VERSION ""

NS_ :

BS_:

BU_: Tester FrontECU MyECU
VAL_TABLE_ SeatHeatLevel 3 "Level3" 2 "Level2" 1 "Level1" 0 "None" ;
VAL_TABLE_ SeatVentilationLevel 3 "Level3" 2 "Level2" 1 "Level1" 0 "None" ;
VAL_TABLE_ PowerModeStatus 3 "ACC" 2 "RUN" 1 "ACC" 0 "OFF" ;

BO_ 3221225472 VECTOR__INDEPENDENT_SIG_MSG: 0 Vector__XXX
 SG_ WindowStatus : 0|4@0+ (1,0) [0|15] "" Vector__XXX
 SG_ SteeringWheelAngle : 0|16@0- (0.1,0) [-3276.8|3276.7] "" Vector__XXX
 SG_ DoorStatus : 0|4@0+ (1,0) [0|15] "" Vector__XXX
 SG_ BrakePedalPosition : 0|10@0+ (0.1,0) [0|102.3] "" Vector__XXX
 SG_ AccPedalPosition : 0|10@0+ (0.1,0) [0|102.3] "" Vector__XXX
 SG_ HeadLampStatus : 0|4@0+ (1,0) [0|15] "" Vector__XXX

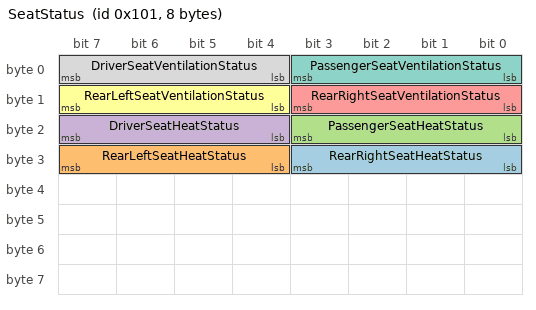
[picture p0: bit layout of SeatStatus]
BO_ 257 SeatStatus: 8 MyECU
 SG_ RearRightSeatHeatStatus : 27|4@0+ (1,0) [0|15] ""  FrontECU
 SG_ RearLeftSeatHeatStatus : 31|4@0+ (1,0) [0|15] ""  FrontECU
 SG_ PassengerSeatHeatStatus : 19|4@0+ (1,0) [0|15] ""  FrontECU
 SG_ DriverSeatHeatStatus : 23|4@0+ (1,0) [0|15] ""  FrontECU
 SG_ RearRightSeatVentilationStatus : 11|4@0+ (1,0) [0|15] ""  FrontECU
 SG_ RearLeftSeatVentilationStatus : 15|4@0+ (1,0) [0|15] ""  FrontECU
 SG_ PassengerSeatVentilationStatus : 3|4@0+ (1,0) [0|15] ""  FrontECU
 SG_ DriverSeatVentilationStatus : 7|4@0+ (1,0) [0|15] ""  FrontECU

CM_ BO_ 3221225472 "This is a message for not used signals, created by Vector CANdb++ DBC OLE DB Provider.";
BA_DEF_ BO_  "GenMsgCycleTime" INT 0 0;
BA_DEF_ BO_  "GenMsgSendType" ENUM  "Cyclic","spontanX","cyclicIfActiveX","spontanWithDelay","cyclicAndSpontanX","cyclicAndSpontanWithDelay","spontanWithRepetition","cyclicIfActiveAndSpontanWD","cyclicIfActiveFast","cyclicWithRepeatOnDemand";
BA_DEF_ SG_  "GenSigSendType" ENUM  "Cyclic","spontanX","cyclicIfActiveX","spontanWithDelay","cyclicAndSpontanX","cyclicAndSpontanWithDelay","spontanWithRepetition","cyclicIfActiveAndSpontanWD","cyclicIfActiveFast","cyclicWithRepeatOnDemand","none","NotUsed","NotUsed";
BA_DEF_  "Baudrate" INT 0 1000000;
BA_DEF_  "BusType" STRING ;
BA_DEF_  "NmType" STRING ;
BA_DEF_  "Manufacturer" STRING ;
BA_DEF_  "NmAsrWaitBusSleepTime" INT 0 65535;
BA_DEF_  "NmAsrTimeoutTime" INT 0 65535;
BA_DEF_  "NmAsrRepeatMessageTime" INT 0 65535;
BA_DEF_ BU_  "NmAsrNodeIdentifier" INT 0 255;
BA_DEF_ BU_  "NmAsrNode" ENUM  "no","yes";
BA_DEF_  "NmAsrMessageCount" INT 0 256;
BA_DEF_ BU_  "NmAsrCanMsgReducedTime" INT 0 65535;
BA_DEF_  "NmAsrCanMsgCycleTime" INT 0 65535;
BA_DEF_  "NmAsrBaseAddress" HEX 0 65535;
BA_DEF_ BU_  "ILUsed" ENUM  "no","yes";
BA_DEF_ BO_  "GenMsgILSupport" ENUM  "no","yes";
BA_DEF_DEF_  "GenMsgCycleTime" 0;
BA_DEF_DEF_  "GenMsgSendType" "Cyclic";
BA_DEF_DEF_  "GenSigSendType" "Cyclic";
BA_DEF_DEF_  "Baudrate" 500000;
BA_DEF_DEF_  "BusType" "";
BA_DEF_DEF_  "NmType" "";
BA_DEF_DEF_  "Manufacturer" "Vector";
BA_DEF_DEF_  "NmAsrWaitBusSleepTime" 750;
BA_DEF_DEF_  "NmAsrTimeoutTime" 1000;
BA_DEF_DEF_  "NmAsrRepeatMessageTime" 400;
BA_DEF_DEF_  "NmAsrNodeIdentifier" 0;
BA_DEF_DEF_  "NmAsrNode" "yes";
BA_DEF_DEF_  "NmAsrMessageCount" 64;
BA_DEF_DEF_  "NmAsrCanMsgReducedTime" 50;
BA_DEF_DEF_  "NmAsrCanMsgCycleTime" 100;
BA_DEF_DEF_  "NmAsrBaseAddress" 1024;
BA_DEF_DEF_  "ILUsed" "yes";
BA_DEF_DEF_  "GenMsgILSupport" "yes";
BA_ "NmType" "NmAsr";
BA_ "BusType" "CAN";
BA_ "Baudrate" 0;
BA_ "NmAsrNodeIdentifier" BU_ FrontECU 1;
BA_ "GenMsgCycleTime" BO_ 257 100;
VAL_ 257 RearRightSeatHeatStatus 3 "Level3" 2 "Level2" 1 "Level1" 0 "None" ;
VAL_ 257 RearLeftSeatHeatStatus 3 "Level3" 2 "Level2" 1 "Level1" 0 "None" ;
VAL_ 257 PassengerSeatHeatStatus 3 "Level3" 2 "Level2" 1 "Level1" 0 "None" ;
VAL_ 257 DriverSeatHeatStatus 3 "Level3" 2 "Level2" 1 "Level1" 0 "None" ;
VAL_ 257 RearRightSeatVentilationStatus 3 "Level3" 2 "Level2" 1 "Level1" 0 "None" ;
VAL_ 257 RearLeftSeatVentilationStatus 3 "Level3" 2 "Level2" 1 "Level1" 0 "None" ;
VAL_ 257 PassengerSeatVentilationStatus 3 "Level3" 2 "Level2" 1 "Level1" 0 "None" ;
VAL_ 257 DriverSeatVentilationStatus 3 "Level3" 2 "Level2" 1 "Level1" 0 "None" ;
